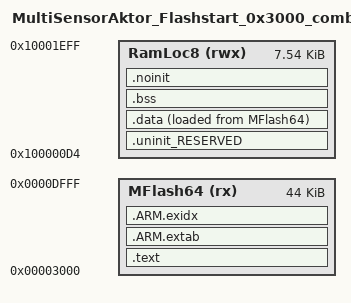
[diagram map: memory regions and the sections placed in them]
/*
 * Based on the generated linker script of firmware_updater/bootloaderupdater.
 * Changed for the MultiSensorAktor: flash ends at 0xE000, where the flash of its MemMapper starts,
 * so an application growing into it fails at link time.
 * Copyright 2008-2013 Code Red Technologies Ltd,
 * Copyright 2013-2026 NXP
 * SPDX-License-Identifier: BSD-3-Clause
 * Generated linker script file for LPC1115/303
 * Created from linkscript.ldt by FMCreateLinkLibraries
 * Using Freemarker v2.3.30
 * MCUXpresso IDE v25.6 [Build 136] [2025-06-27] on 21.04.2026, 03:20:31
 */

GROUP (
  "libgcc.a"
  "libc_nano.a"
  "libstdc++_nano.a"
  "libm.a"
  "libcr_newlib_nohost.a"
  "crti.o"
  "crtn.o"
  "crtbegin.o"
  "crtend.o"
)

MEMORY
{
    /* Define each memory region */
    /******************************************************************
     * Selfbus Flash configuration using build config: Flashstart 0x3000 Debug *
    /******************************************************************/
    MFlash64 (rx) : ORIGIN = 0x3000, LENGTH = 0xE000 - 0x3000
    /****************************************************************
     * Selfbus RAM configuration using build config: Flashstart 0x3000 Debug *
    /****************************************************************/
    RamLoc8 (rwx) : ORIGIN = 0x100000d4, LENGTH = 0x1f00 - 0xd4
}

      /* Define a symbol for the top of each memory region */
      /******************************************************************
       * Selfbus Flash configuration using build config: Flashstart 0x3000 Debug *
      /******************************************************************/
      __base_MFlash64 = 0x3000; /* MFlash64 */
      __base_Flash = 0x3000; /* Flash */
      __top_MFlash64 = 0xE000;
      __top_Flash = 0xE000;
      /****************************************************************
       * Selfbus RAM configuration using build config: Flashstart 0x3000 Debug *
      /****************************************************************/
      __base_RamLoc8 = 0x100000d4; /* RamLoc8 */
      __base_RAM = 0x100000d4; /* RAM */
      __top_RamLoc8 = 0x100000d4 + 0x1f00 - 0xd4;
      __top_RAM = 0x100000d4 + 0x1f00 - 0xd4;

ENTRY(ResetISR)

SECTIONS
{
     /* MAIN TEXT SECTION */
    .text : ALIGN(4)
    {
        FILL(0xff)
        __vectors_start__ = ABSOLUTE(.) ;
        KEEP(*(.isr_vector))
        /* Global Section Table */
        . = ALIGN(4) ;
        __section_table_start = .;
        __data_section_table = .;
        LONG(LOADADDR(.data));
        LONG(    ADDR(.data));
        LONG(  SIZEOF(.data));
        __data_section_table_end = .;
        __bss_section_table = .;
        LONG(    ADDR(.bss));
        LONG(  SIZEOF(.bss));
        __bss_section_table_end = .;
        __section_table_end = . ;
        /* End of Global Section Table */

        *(.after_vectors*)

       *(.text*)
       *(.rodata .rodata.* .constdata .constdata.*)
       . = ALIGN(4);
            /* C++ constructors etc */
            . = ALIGN(4);
            KEEP(*(.init))
            
            . = ALIGN(4);
            __preinit_array_start = .;
            KEEP (*(.preinit_array))
            __preinit_array_end = .;
            
            . = ALIGN(4);
            __init_array_start = .;
            KEEP (*(SORT(.init_array.*)))
            KEEP (*(.init_array))
            __init_array_end = .;
            
            KEEP(*(.fini));
            
            . = ALIGN(4);
            KEEP (*crtbegin.o(.ctors))
            KEEP (*(EXCLUDE_FILE (*crtend.o) .ctors))
            KEEP (*(SORT(.ctors.*)))
            KEEP (*crtend.o(.ctors))
            
            . = ALIGN(4);
            KEEP (*crtbegin.o(.dtors))
            KEEP (*(EXCLUDE_FILE (*crtend.o) .dtors))
            KEEP (*(SORT(.dtors.*)))
            KEEP (*crtend.o(.dtors))
            . = ALIGN(4);
            /* End C++ */
    } > MFlash64
    /*
     * for exception handling/unwind - some Newlib functions (in common
     * with C++ and STDC++) use this.
     */
    .ARM.extab : ALIGN(4)
    {
        *(.ARM.extab* .gnu.linkonce.armextab.*)
    } > MFlash64

    .ARM.exidx : ALIGN(4)
    {
        __exidx_start = .;
        *(.ARM.exidx* .gnu.linkonce.armexidx.*)
        __exidx_end = .;
    } > MFlash64
 
    _etext = .;
        
    /* MAIN DATA SECTION */
    .uninit_RESERVED (NOLOAD) : ALIGN(4)
    {
        _start_uninit_RESERVED = .;
        KEEP(*(.bss.$RESERVED*))
       . = ALIGN(4) ;
        _end_uninit_RESERVED = .;
    } > RamLoc8 AT> RamLoc8

    /* Main DATA section (RamLoc8) */
    .data : ALIGN(4)
    {
       FILL(0xff)
       _data = . ;
       PROVIDE(__start_data_RAM = .) ;
       PROVIDE(__start_data_RamLoc8 = .) ;
       *(vtable)
       *(.ramfunc*)
       KEEP(*(CodeQuickAccess))
       KEEP(*(DataQuickAccess))
       *(RamFunction)
       *(.data*)
       . = ALIGN(4) ;
       _edata = . ;
       PROVIDE(__end_data_RAM = .) ;
       PROVIDE(__end_data_RamLoc8 = .) ;
    } > RamLoc8 AT>MFlash64

    /* MAIN BSS SECTION */
    .bss (NOLOAD) : ALIGN(4)
    {
        _bss = .;
        PROVIDE(__start_bss_RAM = .) ;
        PROVIDE(__start_bss_RamLoc8 = .) ;
        *(.bss*)
        *(COMMON)
        . = ALIGN(4) ;
        _ebss = .;
        PROVIDE(__end_bss_RAM = .) ;
        PROVIDE(__end_bss_RamLoc8 = .) ;
        PROVIDE(end = .);
    } > RamLoc8 AT> RamLoc8

    /* DEFAULT NOINIT SECTION */
    .noinit (NOLOAD): ALIGN(4)
    {
        _noinit = .;
        PROVIDE(__start_noinit_RAM = .) ;
        PROVIDE(__start_noinit_RamLoc8 = .) ;
        *(.noinit*)
         . = ALIGN(4) ;
        _end_noinit = .;
       PROVIDE(__end_noinit_RAM = .) ;
       PROVIDE(__end_noinit_RamLoc8 = .) ;        
    } > RamLoc8 AT> RamLoc8

    PROVIDE(_pvHeapStart = DEFINED(__user_heap_base) ? __user_heap_base : .);

    PROVIDE(_vStackTop = DEFINED(__user_stack_top) ? __user_stack_top : __top_RamLoc8 - 0);

    /* ## Create checksum value (used in startup) ## */
    PROVIDE(__valid_user_code_checksum = 0 - 
                                         (_vStackTop 
                                         + (ResetISR + 1) 
                                         + (( DEFINED(NMI_Handler) ? NMI_Handler : M0_NMI_Handler ) + 1) 
                                         + (( DEFINED(HardFault_Handler) ? HardFault_Handler : M0_HardFault_Handler ) + 1) 
                                         )
           );

    /* Provide basic symbols giving location and size of main text
     * block, including initial values of RW data sections. Note that
     * these will need extending to give a complete picture with
     * complex images (e.g multiple Flash banks).
     */
    _image_start = LOADADDR(.text);
    _image_end = LOADADDR(.data) + SIZEOF(.data);
    _image_size = _image_end - _image_start;
}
